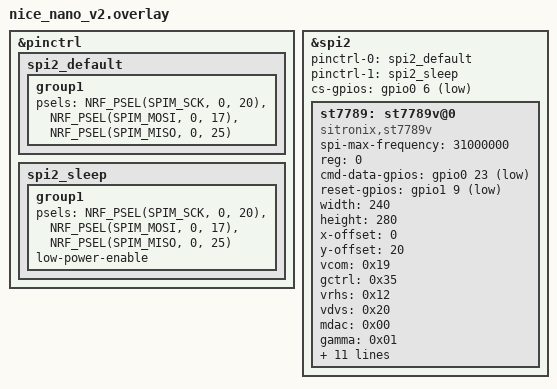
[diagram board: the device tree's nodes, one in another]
&pinctrl {
    spi2_default: spi2_default {
        group1 {
            psels = <NRF_PSEL(SPIM_SCK, 0, 20)>,
                <NRF_PSEL(SPIM_MOSI, 0, 17)>,
                <NRF_PSEL(SPIM_MISO, 0, 25)>;
        };
    };

    spi2_sleep: spi2_sleep {
        group1 {
            psels = <NRF_PSEL(SPIM_SCK, 0, 20)>,
                <NRF_PSEL(SPIM_MOSI, 0, 17)>,
                <NRF_PSEL(SPIM_MISO, 0, 25)>;
            low-power-enable;
        };
    };
};

disp_spi: &spi2 {
   status = "okay";
   pinctrl-0 = <&spi2_default>;
	pinctrl-1 = <&spi2_sleep>;
	pinctrl-names = "default", "sleep";
   cs-gpios = <&gpio0 6 GPIO_ACTIVE_LOW>; //CS

   st7789: st7789v@0 {
       compatible = "sitronix,st7789v";
       spi-max-frequency = <31000000>;
       reg = <0>;
       cmd-data-gpios = <&gpio0 23 GPIO_ACTIVE_LOW>; //DC
       reset-gpios = <&gpio1 9 GPIO_ACTIVE_LOW>; // RES
       width = <240>;
       height = <280>;
       x-offset = <0>;
       y-offset = <20>;
       vcom = <0x19>;
       gctrl = <0x35>;
       vrhs = <0x12>;
       vdvs = <0x20>;
       mdac = <0x00>;
       gamma = <0x01>;
       colmod = <0x05>;
       lcm = <0x2c>;
       porch-param = [ 0c 0c 00 33 33  ];
       cmd2en-param = [ 5a 69 02 01  ];
       pwctrl1-param = [ a4 a1  ];
       pvgam-param = [ D0 04 0D 11 13 2B 3F 54 4C 18 0D 0B 1F 23  ];
       nvgam-param = [ D0 04 0C 11 13 2C 3F 44 51 2F 1F 1F 20 23  ];
       ram-param = [ 00 F0  ];
       rgb-param = [ CD 08 14  ];
   };
};

